# CPSW_CPTS register map
Vendor: Texas Instruments
Peripheral module from a debugger description file (folder am437x).
Registers are 32-bit, access per field, no defined reset value unless marked. A register's access mark holds for its fields unless they carry their own. Offsets are as the file gives them; lines under a group give offsets from that group; [hi:lo] are bit positions; {n}, {i} and the like mark numbered series; 'fields as' and 'values as' point back to an identical list; <NAME> marks a mode.

## CPSW_CPTS
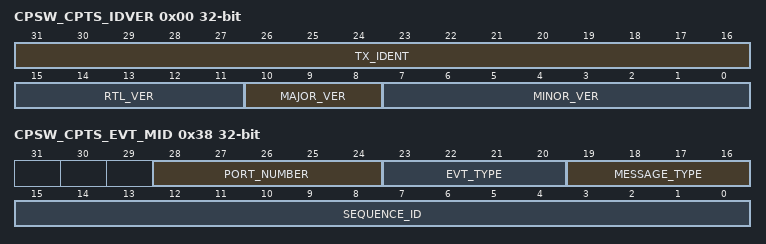
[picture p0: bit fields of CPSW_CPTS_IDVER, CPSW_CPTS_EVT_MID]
0x00 CPSW_CPTS_IDVER ro — IDENTIFICATION AND VERSION REGISTER
  [31:16] TX_IDENT — TX Identification Value
  [15:11] RTL_VER — RTL Version Value
  [10:8] MAJOR_VER — Major Version Value
  [7:0] MINOR_VER — Minor Version Value
0x04 CPSW_CPTS_CTRL — TIME SYNC CONTROL REGISTER
  [31:28] TS_SYNC_SEL rw — TS_SYNC output timestamp counter bit select[[br]] [[br]]0000 - TS_SYNC disabled 0001 to [[br]]1111 - TS_SYNC is timestamp counter bits 31 (1111) down to 17 (0001)
  [15] HW8_TS_PUSH_EN rw — Hardware push 8 enable
  [14] HW7_TS_PUSH_EN rw — Hardware push 7 enable
  [13] HW6_TS_PUSH_EN rw — Hardware push 6 enable
  [13] HW5_TS_PUSH_EN rw — Hardware push 5 enable
  [n+7] HW{n}_TS_PUSH_EN rw (n=1..4) — Hardware push {n} enable
  [1] INT_TEST rw — Interrupt Test - When set, this bit allows the raw interrupt to be written to facilitate interrupt test.
  [0] CPTS_EN rw — Time Sync Enable - When disabled (cleared to zero), the RCLK domain is held in reset.
    1=en_2_0x1 (Time Sync Enabled); 0=en_1_0x0 (Time Sync Disabled)
0x08 CPSW_RFTCLK_SEL — RFTCLK SELECT REGISTER
  [4:0] RFTCLK_SEL rw — Reference Clock Select - This signal is used to control an external multiplexor that selects one of up to 32 clocks for time sync reference (RFTCLK). [[br]]This RFTCLK_SEL value can be written only when the CPTS_EN bit is cleared to zero in the CPTS_CONTROL register.
0x0C CPSW_CPTS_PUSH — TIME STAMP EVENT PUSH REGISTER
  [0] TS_PUSH wo — Time stamp event push - When a logic high is written to this bit a time stamp event is pushed onto the event FIFO. [[br]]The time stamp value is the time of the write of this register, not the time of the event read. [[br]]The time stamp value can then be read on interrupt via the event registers. [[br]]Software should not push a second time stamp event onto the event FIFO until the first time stamp value has been read from the event FIFO (there should be only one time stamp event in the event FIFO at any given time). [[br]]This bit is write only and always reads zero. [[br]]
0x10 CPSW_CPTS_LOAD_VAL rw — TIME STAMP LOAD VALUE REGISTER
  [31:0] TS_LOAD_VAL — Time Stamp Load Value - Writing the ts_load_en bit causes the value contained in this register to be written into the time stamp. [[br]]The time stamp value is read by initiating a time stamp push event, not by reading this register. [[br]]When reading this register, the value read is not the time stamp, but is the value that was last written to this register. [[br]]
0x14 CPSW_CPTS_LOAD_EN — TIME STAMP LOAD ENABLE REGISTER
  [0] TS_LOAD_EN wo — Time Stamp Load - Writing a one to this bit enables the time stamp value to be written via the ts_load_val[[br]][31:0] register. [[br]]This feature is included for test purposes. [[br]]This bit is write only. [[br]]
0x18 CPSW_CPTS_COMP_VAL rw — TIME STAMP COMPARISON VALUE REGISTER
  [31:0] TS_COMP_VAL — Time Stamp Comparison Value Writing a non-zero value to the TS_Comp_Length[15:0] register causes a pulse of TS_Comp_Length RCLK periods on the TS_COMP output and a comparison event when the time_stamp counter value is equivalent to ts_comp_val.
0x1C CPSW_CPTS_COMP_LENGTH — TIME STAMP COMPARISON LENGTH REGISTER
  [15:0] TS_COMP_LENGTH rw — Time Stamp Comparison Length Writing a non-zero value to this field enables the time stamp comparison event and output. [[br]]This value should be zero when the TS_Comp_Val register is written.
0x20 CPSW_CPTS_INTSTAT_RAW — TIME SYNC INTERRUPT STATUS RAW REGISTER
  [0] TS_PEND_RAW rw — TS_PEND_RAW int read (before enable). [[br]]Writable when int_test = 1 A one in this bit indicates that there is one or more events in the event FIFO. [[br]]
0x24 CPSW_CPTS_INTSTAT_MASKED ro — TIME SYNC INTERRUPT STATUS MASKED REGISTER
  [0] TS_PEND — TS_PEND masked interrupt read (after enable).
0x28 CPSW_CPTS_INT_EN — TIME SYNC INTERRUPT ENABLE REGISTER
  [0] TS_PEND_EN rw — TS_PEND masked interrupt enable.
0x30 CPSW_CPTS_EVT_POP — EVENT INTERRUPT POP REGISTER
  [0] EVT_POP wo — Event Pop - When a logic high is written to this bit an event is popped off the event FIFO. [[br]]The event FIFO pop occurs as part of the interrupt process after the event has been read in the Event_Low and Event_High registers. [[br]]Popping an event discards the event and causes the next event, if any, to be moved to the top of the FIFO ready to be read by software on interrupt. [[br]]
0x34 CPSW_CPTS_EVT_LOW ro — LOWER 32-BITS OF THE EVENT VALUE
  [31:0] TIME_STAMP — Time Stamp - The timestamp is valid for transmit, receive, and time stamp push event types. [[br]]The timestamp value is not valid for counter roll event types. [[br]]
0x38 CPSW_CPTS_EVT_MID ro — MIDDLE 32-BITS OF THE EVENT VALUE
  [28:24] PORT_NUMBER — Port Number - indicates the port number of an ethernet event or the hardware push pin number (1 to 4).
  [23:20] EVT_TYPE — Time Sync Event Type
    5=en_6_0x5 (Ethernet Transmit Event); 4=en_5_0x4 (Ethernet Receive Event); 3=en_4_0x3 (Hardware Time Stamp Push Event); 2=en_3_0x2 (Time Stamp Half Rollover Event); 1=en_2_0x1 (Time Stamp Rollover Event); 0=en_1_0x0 (Time Stamp Push Event)
  [19:16] MESSAGE_TYPE — Message type - The message type value that was contained in an ethernet transmit or receive time sync packet. [[br]]This field is valid only for ethernet transmit or receive events. [[br]]
  [15:0] SEQUENCE_ID — Sequence ID - The [[br]]16-bit sequence id is the value that was contained in an ethernet transmit or receivetime sync packet. [[br]]This field is valid only for ethernet transmit or receive events.
0x3C CPSW_CPTS_EVT_HIGH ro — UPPER 32-BITS OF THE EVENT VALUE
  [7:0] DOMAIN — Domain The [[br]]8-bit domain is the value that was contained in an Ethernet transmit or receive time sync packet. [[br]]This field is valid only for Ethernet transmit or receive events.
